# DSP_PRM register map
Vendor: Texas Instruments
Peripheral module from a debugger description file (folder omap4430).
Registers are 32-bit, access not given, reset 0x3F0707 unless marked. A register's access mark holds for its fields unless they carry their own. Offsets are as the file gives them; lines under a group give offsets from that group; [hi:lo] are bit positions; {n}, {i} and the like mark numbered series; 'fields as' and 'values as' point back to an identical list; <NAME> marks a mode.

## DSP_PRM
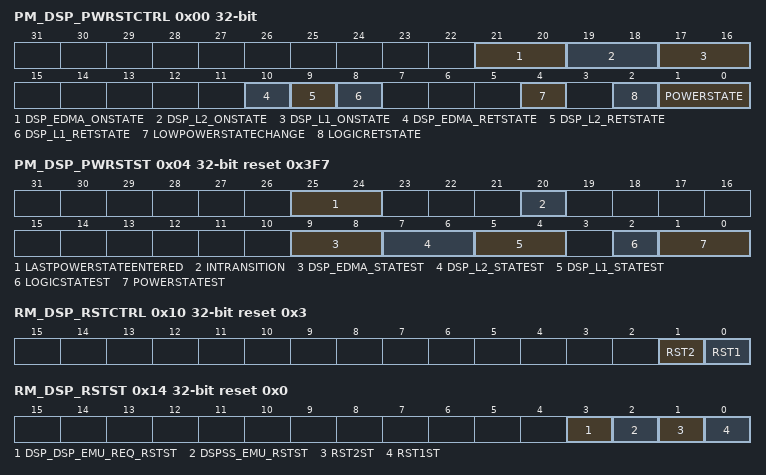
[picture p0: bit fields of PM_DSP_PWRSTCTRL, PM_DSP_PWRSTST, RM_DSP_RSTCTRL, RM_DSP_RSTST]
0x00 PM_DSP_PWRSTCTRL — This register controls the DSP power state to reach upon a domain sleep transition
  [21:20] DSP_EDMA_ONSTATE — DSP_EDMA state when domain is ON. (access R Rreturns1s)
    3=DSP_EDMA_ONSTATE_3_r (Memory bank is on when the domain is ON.)
  [19:18] DSP_L2_ONSTATE — DSP_L2 state when domain is ON. (access R Rreturns1s)
    3=DSP_L2_ONSTATE_3_r (Memory bank is on when the domain is ON.)
  [17:16] DSP_L1_ONSTATE — DSP_L1 state when domain is ON. (access R Rreturns1s)
    3=DSP_L1_ONSTATE_3_r (Memory bank is on when the domain is ON.)
  [10] DSP_EDMA_RETSTATE — DSP_EDMA state when domain is RETENTION. (access R Rreturns1s)
    1=DSP_EDMA_RETSTATE_1_r (Memory bank is retained when domain is in RETENTION state.)
  [9] DSP_L2_RETSTATE rw — DSP_L2 state when domain is RETENTION.
    0=Memory bank is off when the domain is in the RETENTION state; 1=Memory bank is retained when domain is in RETENTION state
  [8] DSP_L1_RETSTATE rw — DSP_L2 state when domain is RETENTION.
    values as DSP_L2_RETSTATE
  [4] LOWPOWERSTATECHANGE — Power state change request when domain has already performed a sleep transition. Allows going into deeper low power state without waking up the power domain. (access RW WSpecial)
    0=Do not request a low power state change; 1=Request a low power state change. This bit is automatically cleared when the power state is effectively changed or when power state is ON.
  [2] LOGICRETSTATE rw — Logic state when power domain is RETENTION
    0=Only retention registers are retained and remaing logic is off when the domain is in RETENTION state; 1=Whole logic is retained when domain is in RETENTION state
  [1:0] POWERSTATE rw — Power state control
    0=OFF state; 1=RETENTION state; 2=INACTIVE state; 3=ON State
0x04 PM_DSP_PWRSTST reset 0x3F7 — This register provides a status on the DSP domain current power state. [warm reset insensitive]
  [25:24] LASTPOWERSTATEENTERED — Last low power state entered. Set to 0x3 upon write of the same only. This register is intended for debug purpose only. (access RW W1toSet)
    3=LASTPOWERSTATEENTERED_3_r (Power domain was previously ON-ACTIVE); 2=LASTPOWERSTATEENTERED_2_r (Power domain was previously ON-INACTIVE); 1=LASTPOWERSTATEENTERED_1_r (Power domain was previously in RETENTION); 0=LASTPOWERSTATEENTERED_0_r (Power domain was previously OFF)
  [20] INTRANSITION ro — Domain transition status
    0=INTRANSITION_0_r (No ongoing transition on power domain); 1=INTRANSITION_1_r (Power domain transition is in progress.)
  [9:8] DSP_EDMA_STATEST ro — DSP_EDMA memory state status
    0=DSP_EDMA_STATEST_0_r (Memory is OFF); 1=DSP_EDMA_STATEST_1_r (Memory is RETENTION); 2=DSP_EDMA_STATEST_2_r (Reserved); 3=DSP_EDMA_STATEST_3_r (Memory is ON)
  [7:6] DSP_L2_STATEST ro — DSP_L2 memory state status
    0=DSP_L2_STATEST_0_r (Memory is OFF); 1=DSP_L2_STATEST_1_r (Memory is RETENTION); 2=DSP_L2_STATEST_2_r (Reserved); 3=DSP_L2_STATEST_3_r (Memory is ON)
  [5:4] DSP_L1_STATEST ro — DSP_L1 memory state status
    0=DSP_L1_STATEST_0_r (Memory is OFF); 1=DSP_L1_STATEST_1_r (Memory is RETENTION); 2=DSP_L1_STATEST_2_r (Reserved); 3=DSP_L1_STATEST_3_r (Memory is ON)
  [2] LOGICSTATEST ro — Logic state status
    0=LOGICSTATEST_0_r (Logic in domain is OFF); 1=LOGICSTATEST_1_r (Logic in domain is ON)
  [1:0] POWERSTATEST ro — Current power state status
    0=POWERSTATEST_0_r (Power domain is OFF); 1=POWERSTATEST_1_r (Power domain is in RETENTION); 2=POWERSTATEST_2_r (Power domain is ON-INACTIVE); 3=POWERSTATEST_3_r (Power domain is ON-ACTIVE)
0x10 RM_DSP_RSTCTRL access per field reset 0x3 — This register controls the release of the DSP sub-system resets.
  [1] RST2 rw — DSP - MMU, cache and slave interface reset control
    0=Reset is cleared for the MMU, cache and slave interface; 1=Reset is asserted for the MMU, cache and slave interface
  [0] RST1 rw — DSP - DSP reset control
    0=Reset is cleared for the DSP - DSP; 1=Reset is asserted for the DSP - DSP
0x14 RM_DSP_RSTST reset 0x0 — This register logs the different reset sources of the DSP domain. Each bit is set upon release of the domain reset signal. Must be cleared by software. [warm reset insensitive]
  [3] DSP_DSP_EMU_REQ_RSTST — DSP DSP processor has been reset due to DSP emulation reset request driven from DSPSS (access RW W1toClr)
    0=No emulation reset; 1=DSP DSP has been reset upon emulation reset request
  [2] DSPSS_EMU_RSTST — DSP domain has been reset due to emulation reset source, that is, assert reset command initiated by the icepick module (access RW W1toClr)
    0=No emulation reset; 1=DSP has been reset upon emulation reset
  [1] RST2ST — DSP MMU, cache and slave interface software reset status (access RW W1toClr)
    0=No software reset occured; 1=MMU, cache and slave interface has been reset upon software reset
  [0] RST1ST — DSP DSP software reset (access RW W1toClr)
    0=No software reset occured; 1=DSP has been reset upon software reset
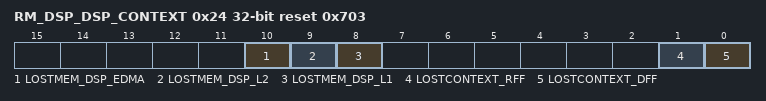
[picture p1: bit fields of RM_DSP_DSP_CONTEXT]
0x24 RM_DSP_DSP_CONTEXT reset 0x703 — This register contains dedicated DSP context statuses. [warm reset insensitive]
  [all] fields
    0=Context has been maintained; 1=Context has been lost
  [10] LOSTMEM_DSP_EDMA — Specify if memory-based context in DSP_EDMA memory bank has been lost due to a previous power transition or other reset source. (access RW W1toClr)
  [9] LOSTMEM_DSP_L2 — Specify if memory-based context in DSP_L2 memory bank has been lost due to a previous power transition or other reset source. (access RW W1toClr)
  [8] LOSTMEM_DSP_L1 — Specify if memory-based context in DSP_L1 memory bank has been lost due to a previous power transition or other reset source. (access RW W1toClr)
  [1] LOSTCONTEXT_RFF — Specify if RFF-based context has been lost due to a previous power transition or other reset source. (set upon assertion of DSP_RET_RST signal) (access RW W1toClr)
  [0] LOSTCONTEXT_DFF — Specify if DFF-based context has been lost due to a previous power transition or other reset source. (set upon assertion of DSP_SYS_RST signal) (access RW W1toClr)
